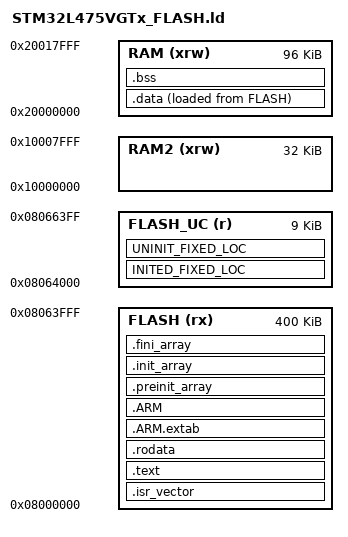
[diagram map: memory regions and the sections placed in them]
/*
*****************************************************************************
**

**  File        : LinkerScript.ld
**
**  Abstract    : Linker script for STM32L475VGTx Device with
**                1024KByte FLASH, 96KByte RAM
**
**                Set heap size, stack size and stack location according
**                to application requirements.
**
**                Set memory bank area and size if external memory is used.
**
**  Target      : STMicroelectronics STM32
**
**
**  Distribution: The file is distributed as is, without any warranty
**                of any kind.
**
**  (c)Copyright Ac6.
**  You may use this file as-is or modify it according to the needs of your
**  project. Distribution of this file (unmodified or modified) is not
**  permitted. Ac6 permit registered System Workbench for MCU users the
**  rights to distribute the assembled, compiled & linked contents of this
**  file as part of an application binary file, provided that it is built
**  using the System Workbench for MCU toolchain.
**
*****************************************************************************
*/

/* Entry Point */
ENTRY(Reset_Handler)

/* Highest address of the user mode stack */
_estack  = 0x20018000;          /* end of RAM */
_estack2_start = 0x10000000;    /* end of RAM2 */
_estack2       = 0x10008000;    /* end of RAM2 */
/* Generate a link error if heap and stack don't fit into RAM */
_Min_Heap_Size = 0x7000;      /* required amount of heap  */
_Min_Stack_Size = 0x2000; /* required amount of stack */

/* Specify the memory areas */
MEMORY
{
RAM (xrw)      : ORIGIN = 0x20000000, LENGTH = 96K
RAM2 (xrw)      : ORIGIN = 0x10000000, LENGTH = 32K
FLASH (rx)      : ORIGIN = 0x8000000, LENGTH = 400K		/* Use only the first bank */
FLASH_UC (r)	: ORIGIN = 0x08064000, LENGTH = 9K		/* Fixed-location area */
}

/* Define output sections */
SECTIONS
{

  INITED_FIXED_LOC : ALIGN(0x800)
  {
    *(INITED_FIXED_LOC)
  } >FLASH_UC
  
  /* uninit region must be last or else it is erased */
  UNINIT_FIXED_LOC (NOLOAD) : ALIGN(0x800)
  {
    *(UNINIT_FIXED_LOC)
  } >FLASH_UC

  /* The startup code goes first into FLASH */
  .isr_vector :
  {
    . = ALIGN(8);
    KEEP(*(.isr_vector)) /* Startup code */
    . = ALIGN(8);
  } >FLASH

  /* The program code and other data goes into FLASH */
  .text :
  {
    . = ALIGN(8);
    *(.text)           /* .text sections (code) */
    *(.text*)          /* .text* sections (code) */
    *(.glue_7)         /* glue arm to thumb code */
    *(.glue_7t)        /* glue thumb to arm code */
    *(.eh_frame)

    KEEP (*(.init))
    KEEP (*(.fini))

    . = ALIGN(8);
    _etext = .;        /* define a global symbols at end of code */
  } >FLASH

  /* Constant data goes into FLASH */
  .rodata :
  {
    . = ALIGN(8);
    *(.rodata)         /* .rodata sections (constants, strings, etc.) */
    *(.rodata*)        /* .rodata* sections (constants, strings, etc.) */
    . = ALIGN(8);
  } >FLASH

  .ARM.extab   : 
  { 
  . = ALIGN(8);
  *(.ARM.extab* .gnu.linkonce.armextab.*)
  . = ALIGN(8);
  } >FLASH
  .ARM : {
	. = ALIGN(8);
    __exidx_start = .;
    *(.ARM.exidx*)
    __exidx_end = .;
	. = ALIGN(8);
  } >FLASH

  .preinit_array     :
  {
	. = ALIGN(8);
    PROVIDE_HIDDEN (__preinit_array_start = .);
    KEEP (*(.preinit_array*))
    PROVIDE_HIDDEN (__preinit_array_end = .);
	. = ALIGN(8);
  } >FLASH
  
  .init_array :
  {
	. = ALIGN(8);
    PROVIDE_HIDDEN (__init_array_start = .);
    KEEP (*(SORT(.init_array.*)))
    KEEP (*(.init_array*))
    PROVIDE_HIDDEN (__init_array_end = .);
	. = ALIGN(8);
  } >FLASH
 
  .fini_array :
  {
	. = ALIGN(8);
    PROVIDE_HIDDEN (__fini_array_start = .);
    KEEP (*(SORT(.fini_array.*)))
    KEEP (*(.fini_array*))
    PROVIDE_HIDDEN (__fini_array_end = .);
	. = ALIGN(8);
  } >FLASH
  

  /* used by the startup to initialize data */
  _sidata = LOADADDR(.data);

  /* Initialized data sections goes into RAM, load LMA copy after code */
  .data : 
  {
    . = ALIGN(8);
    _sdata = .;        /* create a global symbol at data start */
    *(.data)           /* .data sections */
    *(.data*)          /* .data* sections */

    . = ALIGN(8);
    _edata = .;        /* define a global symbol at data end */
  } >RAM AT> FLASH

  
  /* Uninitialized data section */
  . = ALIGN(4);
  .bss :
  {
    /* This is used by the startup in order to initialize the .bss secion */
    _sbss = .;         /* define a global symbol at bss start */
    __bss_start__ = _sbss;
    *(.bss)
    *(.bss*)
    *(COMMON)

    . = ALIGN(4);
    _ebss = .;         /* define a global symbol at bss end */
    __bss_end__ = _ebss;
  } >RAM

  /* User_heap_stack section, used to check that there is enough RAM left */
    . = ALIGN(8);
    PROVIDE ( end = . );
    PROVIDE ( _end = . );
    PROVIDE (heap_start = . );
    PROVIDE(_stack_unused      = _estack - _Min_Stack_Size); /* 0x10*/

    ASSERT ((_stack_unused > end), "Error: No room left for the stack")

    PROVIDE(heap_end      = _stack_unused);
    PROVIDE(heap_len      = heap_end -  heap_start);
    PROVIDE(heap2_start   = _estack2_start);
    PROVIDE(heap2_len     = _estack2 - heap2_start);
    .ARM.attributes 0 : { *(.ARM.attributes) }
}

 GROUP(
   libgcc.a
   libg.a
   libc.a
   libm.a
   libnosys.a
 )



